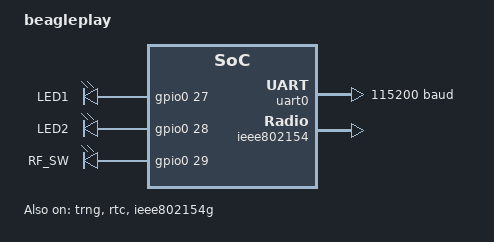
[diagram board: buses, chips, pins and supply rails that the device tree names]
/*
 * Copyright (c) 2022 Jason Kridner, BeagleBoard.org Foundation
 *
 * SPDX-License-Identifier: Apache-2.0
 */

/dts-v1/;

#include <ti/cc1352r7.dtsi>
#include "beagleplay-cc1352-pinctrl.dtsi"

/ {
	model = "beagleplay";
	compatible = "beagle,beagleplay-cc1352";

	aliases {
		led0 = &led0;
		led1 = &led1;
	};

	chosen {
		zephyr,sram = &sram0;
		zephyr,console = &uart0;
		zephyr,shell-uart = &uart0;
		zephyr,flash = &flash0;
		zephyr,ieee802154 = &ieee802154g;
	};

	leds: leds {
		compatible = "gpio-leds";
		led0: led_0 {
			gpios = <&gpio0 27 GPIO_ACTIVE_HIGH>;
			label = "LED1";
		};

		led1: led_1 {
			gpios = <&gpio0 28 GPIO_ACTIVE_HIGH>;
			label = "LED2";
		};

		/* U.FL connector switch */
		rf_sw: rf_sw {
			label = "RF_SW";
			gpios =
				<&gpio0 29 GPIO_ACTIVE_HIGH>, // SubG TX +20dB
				<&gpio0 30 GPIO_ACTIVE_HIGH>; // SubG TX/RX 0dB
		};
	};
};

&cpu0 {
	clock-frequency = <48000000>;
	cpu-power-states = <&idle &standby>;
};

&trng {
	status = "okay";
};

&gpio0 {
	status = "okay";
};

&uart0 {
	status = "okay";
	current-speed = <115200>;
	pinctrl-0 = <&uart0_rx_default &uart0_tx_default>;
	pinctrl-names = "default";
};

&rtc {
	status = "okay";
};

&ieee802154 {
	status = "okay";
};

&ieee802154g {
	status = "okay";
};
